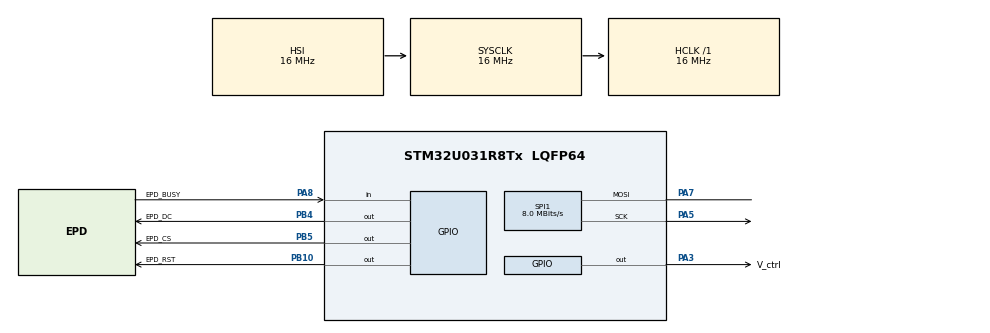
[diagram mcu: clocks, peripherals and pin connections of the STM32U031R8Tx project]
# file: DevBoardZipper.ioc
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Mcu.Family=STM32U0
Mcu.Name=STM32U031R8Tx
Mcu.Package=LQFP64
NVIC.PriorityGroup=NVIC_PRIORITYGROUP_2
PA3.GPIO_Label=V_ctrl
PA3.GPIO_PuPd=GPIO_PULLUP
PA3.PinState=GPIO_PIN_SET
PA3.Signal=GPIO_Output
PA5.GPIO_Speed=GPIO_SPEED_FREQ_VERY_HIGH
PA5.Mode=Simplex_Bidirectional_Master
PA5.Signal=SPI1_SCK
PA7.GPIO_Speed=GPIO_SPEED_FREQ_VERY_HIGH
PA7.Mode=Simplex_Bidirectional_Master
PA7.Signal=SPI1_MOSI
PA8.GPIO_Label=EPD_BUSY
PA8.Signal=GPIO_Input
PB10.GPIO_Label=EPD_RST
PB10.Signal=GPIO_Output
PB4.GPIO_Label=EPD_DC
PB4.Signal=GPIO_Output
PB5.GPIO_Label=EPD_CS
PB5.GPIO_PuPd=GPIO_PULLUP
PB5.GPIO_Speed=GPIO_SPEED_FREQ_VERY_HIGH
PB5.Signal=GPIO_Output
ProjectManager.HeapSize=0x200
ProjectManager.StackSize=0x400
ProjectManager.TargetToolchain=STM32CubeIDE
RCC.AHBFreq_Value=16000000
RCC.CortexFreq_Value=16000000
RCC.HCLKFreq_Value=16000000
RCC.HSE_VALUE=4000000
RCC.HSI48_VALUE=48000000
RCC.HSI_VALUE=16000000
RCC.LSE_VALUE=32768
RCC.MSI_VALUE=4000000
RCC.SYSCLKFreq_VALUE=16000000
RCC.VCOOutputFreq_Value=64000000
SPI1.BaudRatePrescaler=SPI_BAUDRATEPRESCALER_2
SPI1.CLKPhase=SPI_PHASE_1EDGE
SPI1.CLKPolarity=SPI_POLARITY_LOW
SPI1.CalculateBaudRate=8.0 MBits/s
SPI1.DataSize=SPI_DATASIZE_8BIT
SPI1.Direction=SPI_DIRECTION_1LINE
SPI1.Mode=SPI_MODE_MASTER
SPI1.VirtualType=VM_MASTER
VP_PWR_VS_SECSignals.Mode=Security/Privilege
board=custom

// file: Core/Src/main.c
/* USER CODE BEGIN Header */
/**
  ******************************************************************************
  * @file           : main.c
  * @brief          : Main program body
  ******************************************************************************
  * @attention
  *
  * Copyright (c) 2026 STMicroelectronics.
  * All rights reserved.
  *
  * This software is licensed under terms that can be found in the LICENSE file
  * in the root directory of this software component.
  * If no LICENSE file comes with this software, it is provided AS-IS.
  *
  ******************************************************************************
  */
/* USER CODE END Header */
#include "main.h"

/* USER CODE BEGIN Includes */
#include "zipper_screen.h"
#include <stdbool.h>

/* USER CODE END Includes */

/* USER CODE BEGIN PV */
SPI_HandleTypeDef hspi1;
/* USER CODE END PV */

void SystemClock_Config(void);
static void MX_GPIO_Init(void);
static void MX_SPI1_Init(void);

int main(void)
{

  /* MCU Configuration--------------------------------------------------------*/

  /* Reset of all peripherals, Initializes the Flash interface and the Systick. */
  HAL_Init();

  /* USER CODE BEGIN Init */
  HAL_GPIO_WritePin(V_ctrl_GPIO_Port, V_ctrl_Pin, GPIO_PIN_SET);
  /* USER CODE END Init */

  /* Configure the system clock */
  SystemClock_Config();

  /* Initialize all configured peripherals */
  MX_GPIO_Init();
  MX_SPI1_Init();
  /* USER CODE BEGIN 2 */

  initialize_screen(&hspi1);
  write_main_alt(7228, true);

  for(int i = 100; i < 105; i++)
  {
	  write_main_alt(i, false);
  }
  seal();
  /* USER CODE END 2 */

  /* Infinite loop */
  while (1)
  {

  }
}

void SystemClock_Config(void)
{
  RCC_OscInitTypeDef RCC_OscInitStruct = {0};
  RCC_ClkInitTypeDef RCC_ClkInitStruct = {0};

  /** Configure the main internal regulator output voltage
  */
  HAL_PWREx_ControlVoltageScaling(PWR_REGULATOR_VOLTAGE_SCALE2);

  /** Initializes the RCC Oscillators according to the specified parameters
  * in the RCC_OscInitTypeDef structure.
  */
  RCC_OscInitStruct.OscillatorType = RCC_OSCILLATORTYPE_HSI;
  RCC_OscInitStruct.HSIState = RCC_HSI_ON;
  RCC_OscInitStruct.HSICalibrationValue = RCC_HSICALIBRATION_DEFAULT;
  RCC_OscInitStruct.PLL.PLLState = RCC_PLL_NONE;
  if (HAL_RCC_OscConfig(&RCC_OscInitStruct) != HAL_OK)
  {
    Error_Handler();
  }

  /** Initializes the CPU, AHB and APB buses clocks
  */
  RCC_ClkInitStruct.ClockType = RCC_CLOCKTYPE_HCLK|RCC_CLOCKTYPE_SYSCLK
                              |RCC_CLOCKTYPE_PCLK1;
  RCC_ClkInitStruct.SYSCLKSource = RCC_SYSCLKSOURCE_HSI;
  RCC_ClkInitStruct.AHBCLKDivider = RCC_SYSCLK_DIV1;
  RCC_ClkInitStruct.APB1CLKDivider = RCC_HCLK_DIV1;

  if (HAL_RCC_ClockConfig(&RCC_ClkInitStruct, FLASH_LATENCY_1) != HAL_OK)
  {
    Error_Handler();
  }
}

static void MX_SPI1_Init(void)
{

  /* SPI1 parameter configuration*/
  hspi1.Instance = SPI1;
  hspi1.Init.Mode = SPI_MODE_MASTER;
  hspi1.Init.Direction = SPI_DIRECTION_1LINE;
  hspi1.Init.DataSize = SPI_DATASIZE_8BIT;
  hspi1.Init.CLKPolarity = SPI_POLARITY_LOW;
  hspi1.Init.CLKPhase = SPI_PHASE_1EDGE;
  hspi1.Init.NSS = SPI_NSS_SOFT;
  hspi1.Init.BaudRatePrescaler = SPI_BAUDRATEPRESCALER_2;
  hspi1.Init.FirstBit = SPI_FIRSTBIT_MSB;
  hspi1.Init.TIMode = SPI_TIMODE_DISABLE;
  hspi1.Init.CRCCalculation = SPI_CRCCALCULATION_DISABLE;
  hspi1.Init.CRCPolynomial = 7;
  hspi1.Init.CRCLength = SPI_CRC_LENGTH_DATASIZE;
  hspi1.Init.NSSPMode = SPI_NSS_PULSE_ENABLE;
  if (HAL_SPI_Init(&hspi1) != HAL_OK)
  {
    Error_Handler();
  }

}

static void MX_GPIO_Init(void)
{
  GPIO_InitTypeDef GPIO_InitStruct = {0};

  /* GPIO Ports Clock Enable */
  __HAL_RCC_GPIOA_CLK_ENABLE();
  __HAL_RCC_GPIOB_CLK_ENABLE();

  /*Configure GPIO pin Output Level */
  HAL_GPIO_WritePin(V_ctrl_GPIO_Port, V_ctrl_Pin, GPIO_PIN_SET);

  /*Configure GPIO pin Output Level */
  HAL_GPIO_WritePin(GPIOB, EPD_RST_Pin|EPD_DC_Pin|EPD_CS_Pin, GPIO_PIN_RESET);

  /*Configure GPIO pin : V_ctrl_Pin */
  GPIO_InitStruct.Pin = V_ctrl_Pin;
  GPIO_InitStruct.Mode = GPIO_MODE_OUTPUT_PP;
  GPIO_InitStruct.Pull = GPIO_PULLUP;
  GPIO_InitStruct.Speed = GPIO_SPEED_FREQ_LOW;
  HAL_GPIO_Init(V_ctrl_GPIO_Port, &GPIO_InitStruct);

  /*Configure GPIO pins : EPD_RST_Pin EPD_DC_Pin */
  GPIO_InitStruct.Pin = EPD_RST_Pin|EPD_DC_Pin;
  GPIO_InitStruct.Mode = GPIO_MODE_OUTPUT_PP;
  GPIO_InitStruct.Pull = GPIO_NOPULL;
  GPIO_InitStruct.Speed = GPIO_SPEED_FREQ_LOW;
  HAL_GPIO_Init(GPIOB, &GPIO_InitStruct);

  /*Configure GPIO pin : EPD_BUSY_Pin */
  GPIO_InitStruct.Pin = EPD_BUSY_Pin;
  GPIO_InitStruct.Mode = GPIO_MODE_INPUT;
  GPIO_InitStruct.Pull = GPIO_NOPULL;
  HAL_GPIO_Init(EPD_BUSY_GPIO_Port, &GPIO_InitStruct);

  /*Configure GPIO pin : EPD_CS_Pin */
  GPIO_InitStruct.Pin = EPD_CS_Pin;
  GPIO_InitStruct.Mode = GPIO_MODE_OUTPUT_PP;
  GPIO_InitStruct.Pull = GPIO_PULLUP;
  GPIO_InitStruct.Speed = GPIO_SPEED_FREQ_VERY_HIGH;
  HAL_GPIO_Init(EPD_CS_GPIO_Port, &GPIO_InitStruct);

}

void Error_Handler(void)
{
  __disable_irq();
  while (1)
  {
  }
}
